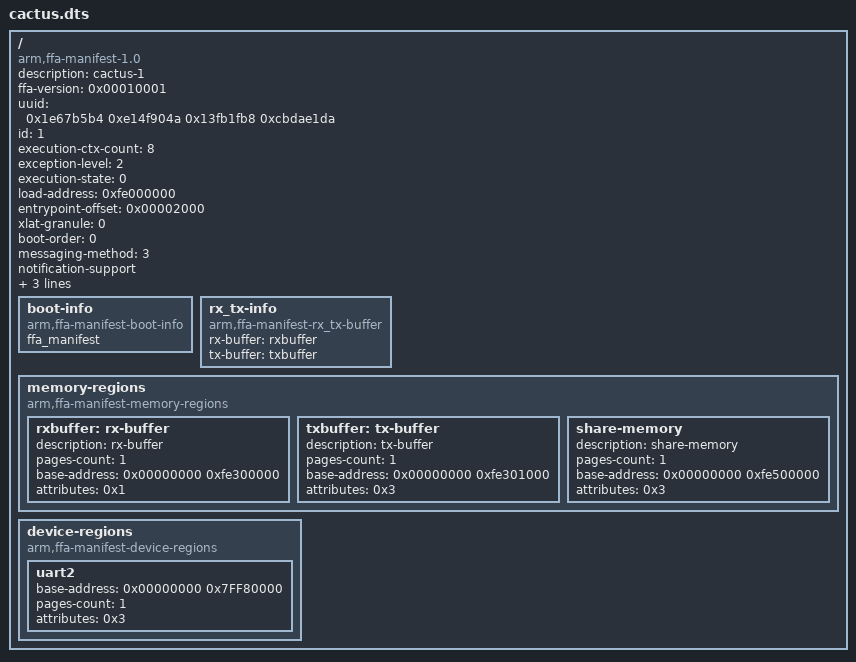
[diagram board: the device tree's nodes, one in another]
/*
 * Copyright (c) 2020-2021, Arm Limited. All rights reserved.
 *
 * SPDX-License-Identifier: BSD-3-Clause
 *
 * This file is a Partition Manifest (PM) for a minimal Secure Partition (SP)
 * that has additional optional properties defined.
 *
 */

/dts-v1/;

/ {
	compatible = "arm,ffa-manifest-1.0";

	/* Properties */
	description = "cactus-1";
	ffa-version = <0x00010001>; /* 31:16 - Major, 15:0 - Minor */
	uuid = <0x1e67b5b4 0xe14f904a 0x13fb1fb8 0xcbdae1da>;
	id = <1>;
	execution-ctx-count = <8>;
	exception-level = <2>; /* S-EL1 */
	execution-state = <0>; /* AARCH64 */
	load-address = <0xfe000000>;
	entrypoint-offset = <0x00002000>;
	xlat-granule = <0>; /* 4KiB */
	boot-order = <0>;
	messaging-method = <3>; /* Direct messaging only */
	notification-support; /* Support receipt of notifications. */
	managed-exit; /* Managed exit supported */
	run-time-model = <1>; /* Run to completion */

	/* Boot protocol */
	gp-register-num = <0>;

	/* Boot Info */
	boot-info {
		compatible = "arm,ffa-manifest-boot-info";
		ffa_manifest;
	};

	rx_tx-info {
		compatible = "arm,ffa-manifest-rx_tx-buffer";
		rx-buffer = <&rxbuffer>;
		tx-buffer = <&txbuffer>;
	};

	memory-regions {
		compatible = "arm,ffa-manifest-memory-regions";

		rxbuffer: rx-buffer {
			description = "rx-buffer";
			pages-count = <1>;
			base-address = <0x00000000 0xfe300000>;
			attributes = <0x1>; /* read-only */
		};

		txbuffer: tx-buffer {
			description = "tx-buffer";
			pages-count = <1>;
			base-address = <0x00000000 0xfe301000>;
			attributes = <0x3>; /* read-write */
		};

		/* Memory to be shared in memory sharing tests. */
		share-memory {
			description = "share-memory";
			pages-count = <1>;
			base-address =<0x00000000 0xfe500000>;
			attributes = <0x3>; /* read-write */
		};
	};

	device-regions {
		compatible = "arm,ffa-manifest-device-regions";
		uart2 {
			base-address = <0x00000000 0x7FF80000>;
			pages-count = <1>;
			attributes = <0x3>; /* read-write */
		};
	};
};
